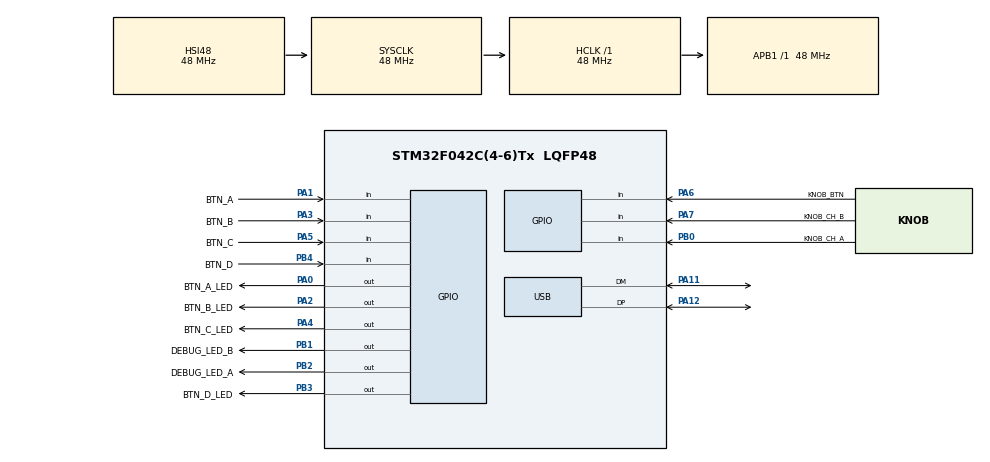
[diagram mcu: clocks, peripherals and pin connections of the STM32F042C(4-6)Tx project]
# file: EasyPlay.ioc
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Mcu.Family=STM32F0
Mcu.Name=STM32F042C(4-6)Tx
Mcu.Package=LQFP48
NVIC.TIM2_IRQn=true\:0\:0\:false\:false\:true\:true\:true\:true
NVIC.USB_IRQn=true\:0\:0\:false\:false\:true\:true\:true\:true
PA0.GPIO_Label=BTN_A_LED
PA0.Signal=GPIO_Output
PA1.GPIO_Label=BTN_A
PA1.Signal=GPIO_Input
PA11.Mode=Device
PA11.Signal=USB_DM
PA12.Mode=Device
PA12.Signal=USB_DP
PA13.Mode=Serial_Wire
PA13.Signal=SYS_SWDIO
PA14.Mode=Serial_Wire
PA14.Signal=SYS_SWCLK
PA2.GPIO_Label=BTN_B_LED
PA2.Signal=GPIO_Output
PA3.GPIO_Label=BTN_B
PA3.Signal=GPIO_Input
PA4.GPIO_Label=BTN_C_LED
PA4.Signal=GPIO_Output
PA5.GPIO_Label=BTN_C
PA5.Signal=GPIO_Input
PA6.GPIO_Label=KNOB_BTN
PA6.Signal=GPIO_Input
PA7.GPIO_Label=KNOB_CH_B
PA7.Signal=GPIO_Input
PB0.GPIO_Label=KNOB_CH_A
PB0.Signal=GPIO_Input
PB1.GPIO_Label=DEBUG_LED_B
PB1.Signal=GPIO_Output
PB2.GPIO_Label=DEBUG_LED_A
PB2.Signal=GPIO_Output
PB3.GPIO_Label=BTN_D_LED
PB3.Signal=GPIO_Output
PB4.GPIO_Label=BTN_D
PB4.Signal=GPIO_Input
ProjectManager.HeapSize=0x0
ProjectManager.StackSize=0x0
ProjectManager.TargetToolchain=STM32CubeIDE
RCC.AHBFreq_Value=48000000
RCC.APB1Freq_Value=48000000
RCC.APB1TimFreq_Value=48000000
RCC.HCLKFreq_Value=48000000
RCC.HSE_VALUE=25000000
RCC.SYSCLKFreq_VALUE=48000000
RCC.SYSCLKSource=RCC_SYSCLKSOURCE_HSI48
TIM2.AutoReloadPreload=TIM_AUTORELOAD_PRELOAD_ENABLE
TIM2.Period=48
TIM2.Prescaler=1000
USB_DEVICE.APP_RX_DATA_SIZE=15
USB_DEVICE.APP_TX_DATA_SIZE=15
USB_DEVICE.CLASS_NAME_FS=CDC
USB_DEVICE.PRODUCT_STRING_CDC_FS=EasyPlayDevice
USB_DEVICE.VirtualMode=Cdc
USB_DEVICE.VirtualModeFS=Cdc_FS
VP_TIM2_VS_ClockSourceINT.Mode=Internal
VP_USB_DEVICE_VS_USB_DEVICE_CDC_FS.Mode=CDC_FS
board=custom

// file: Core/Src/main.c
/* USER CODE BEGIN Header */
/**
 ******************************************************************************
 * @file           : main.c
 * @brief          : Main program body
 ******************************************************************************
 * @attention
 *
 * Copyright (c) 2022 STMicroelectronics.
 * All rights reserved.
 *
 * This software is licensed under terms that can be found in the LICENSE file
 * in the root directory of this software component.
 * If no LICENSE file comes with this software, it is provided AS-IS.
 *
 ******************************************************************************
 */
/* USER CODE END Header */
#include "main.h"
#include "usb_device.h"

/* USER CODE BEGIN Includes */
#include <debug_leds.h>
#include <tasks.h>
#include <ui_master.h>
#include <usb_comm.h>
/* USER CODE END Includes */

/* USER CODE BEGIN PD */
#define STABILIZING_PERIOD_MS 100
/* USER CODE END PD */

TIM_HandleTypeDef htim2;

void SystemClock_Config(void);
static void MX_GPIO_Init(void);
static void MX_TIM2_Init(void);

int main(void)
{

  /* MCU Configuration--------------------------------------------------------*/

  /* Reset of all peripherals, Initializes the Flash interface and the Systick. */
  HAL_Init();

  /* Configure the system clock */
  SystemClock_Config();

  /* Initialize all configured peripherals */
  MX_GPIO_Init();
  MX_USB_DEVICE_Init();
  MX_TIM2_Init();
  /* USER CODE BEGIN 2 */
  init_USB_queues();
  init_sws_debounce_data();
  HAL_Delay(STABILIZING_PERIOD_MS);
  /* USER CODE END 2 */

  /* Infinite loop */
  while (1) {

    /* USER CODE BEGIN 3 */
    run_schedule();
  }
  /* USER CODE END 3 */
}

void SystemClock_Config(void)
{
  RCC_OscInitTypeDef RCC_OscInitStruct = {0};
  RCC_ClkInitTypeDef RCC_ClkInitStruct = {0};
  RCC_PeriphCLKInitTypeDef PeriphClkInit = {0};

  /** Initializes the RCC Oscillators according to the specified parameters
  * in the RCC_OscInitTypeDef structure.
  */
  RCC_OscInitStruct.OscillatorType = RCC_OSCILLATORTYPE_HSI48;
  RCC_OscInitStruct.HSI48State = RCC_HSI48_ON;
  RCC_OscInitStruct.PLL.PLLState = RCC_PLL_NONE;
  if (HAL_RCC_OscConfig(&RCC_OscInitStruct) != HAL_OK)
  {
    Error_Handler();
  }

  /** Initializes the CPU, AHB and APB buses clocks
  */
  RCC_ClkInitStruct.ClockType = RCC_CLOCKTYPE_HCLK|RCC_CLOCKTYPE_SYSCLK
                              |RCC_CLOCKTYPE_PCLK1;
  RCC_ClkInitStruct.SYSCLKSource = RCC_SYSCLKSOURCE_HSI48;
  RCC_ClkInitStruct.AHBCLKDivider = RCC_SYSCLK_DIV1;
  RCC_ClkInitStruct.APB1CLKDivider = RCC_HCLK_DIV1;

  if (HAL_RCC_ClockConfig(&RCC_ClkInitStruct, FLASH_LATENCY_1) != HAL_OK)
  {
    Error_Handler();
  }
  PeriphClkInit.PeriphClockSelection = RCC_PERIPHCLK_USB;
  PeriphClkInit.UsbClockSelection = RCC_USBCLKSOURCE_HSI48;

  if (HAL_RCCEx_PeriphCLKConfig(&PeriphClkInit) != HAL_OK)
  {
    Error_Handler();
  }
}

static void MX_TIM2_Init(void)
{

  TIM_ClockConfigTypeDef sClockSourceConfig = {0};
  TIM_MasterConfigTypeDef sMasterConfig = {0};

  htim2.Instance = TIM2;
  htim2.Init.Prescaler = 1000;
  htim2.Init.CounterMode = TIM_COUNTERMODE_UP;
  htim2.Init.Period = 48;
  htim2.Init.ClockDivision = TIM_CLOCKDIVISION_DIV1;
  htim2.Init.AutoReloadPreload = TIM_AUTORELOAD_PRELOAD_ENABLE;
  if (HAL_TIM_Base_Init(&htim2) != HAL_OK)
  {
    Error_Handler();
  }
  sClockSourceConfig.ClockSource = TIM_CLOCKSOURCE_INTERNAL;
  if (HAL_TIM_ConfigClockSource(&htim2, &sClockSourceConfig) != HAL_OK)
  {
    Error_Handler();
  }
  sMasterConfig.MasterOutputTrigger = TIM_TRGO_RESET;
  sMasterConfig.MasterSlaveMode = TIM_MASTERSLAVEMODE_DISABLE;
  if (HAL_TIMEx_MasterConfigSynchronization(&htim2, &sMasterConfig) != HAL_OK)
  {
    Error_Handler();
  }
  /* USER CODE BEGIN TIM2_Init 2 */
  HAL_TIM_Base_Start_IT(&htim2);
  /* USER CODE END TIM2_Init 2 */

}

static void MX_GPIO_Init(void)
{
  GPIO_InitTypeDef GPIO_InitStruct = {0};

  /* GPIO Ports Clock Enable */
  __HAL_RCC_GPIOA_CLK_ENABLE();
  __HAL_RCC_GPIOB_CLK_ENABLE();

  /*Configure GPIO pin Output Level */
  HAL_GPIO_WritePin(GPIOA, BTN_A_LED_Pin|BTN_B_LED_Pin|BTN_C_LED_Pin, GPIO_PIN_RESET);

  /*Configure GPIO pin Output Level */
  HAL_GPIO_WritePin(GPIOB, DEBUG_LED_B_Pin|DEBUG_LED_A_Pin|BTN_D_LED_Pin, GPIO_PIN_RESET);

  /*Configure GPIO pins : BTN_A_LED_Pin BTN_B_LED_Pin BTN_C_LED_Pin */
  GPIO_InitStruct.Pin = BTN_A_LED_Pin|BTN_B_LED_Pin|BTN_C_LED_Pin;
  GPIO_InitStruct.Mode = GPIO_MODE_OUTPUT_PP;
  GPIO_InitStruct.Pull = GPIO_NOPULL;
  GPIO_InitStruct.Speed = GPIO_SPEED_FREQ_LOW;
  HAL_GPIO_Init(GPIOA, &GPIO_InitStruct);

  /*Configure GPIO pins : BTN_A_Pin BTN_B_Pin BTN_C_Pin KNOB_BTN_Pin
                           KNOB_CH_B_Pin */
  GPIO_InitStruct.Pin = BTN_A_Pin|BTN_B_Pin|BTN_C_Pin|KNOB_BTN_Pin
                          |KNOB_CH_B_Pin;
  GPIO_InitStruct.Mode = GPIO_MODE_INPUT;
  GPIO_InitStruct.Pull = GPIO_NOPULL;
  HAL_GPIO_Init(GPIOA, &GPIO_InitStruct);

  /*Configure GPIO pins : KNOB_CH_A_Pin BTN_D_Pin */
  GPIO_InitStruct.Pin = KNOB_CH_A_Pin|BTN_D_Pin;
  GPIO_InitStruct.Mode = GPIO_MODE_INPUT;
  GPIO_InitStruct.Pull = GPIO_NOPULL;
  HAL_GPIO_Init(GPIOB, &GPIO_InitStruct);

  /*Configure GPIO pins : DEBUG_LED_B_Pin DEBUG_LED_A_Pin BTN_D_LED_Pin */
  GPIO_InitStruct.Pin = DEBUG_LED_B_Pin|DEBUG_LED_A_Pin|BTN_D_LED_Pin;
  GPIO_InitStruct.Mode = GPIO_MODE_OUTPUT_PP;
  GPIO_InitStruct.Pull = GPIO_NOPULL;
  GPIO_InitStruct.Speed = GPIO_SPEED_FREQ_LOW;
  HAL_GPIO_Init(GPIOB, &GPIO_InitStruct);

}

void Error_Handler(void)
{
  /* USER CODE BEGIN Error_Handler_Debug */
  /* User can add his own implementation to report the HAL error return state */
  __disable_irq();
  while (1) {
    set_problem_LED_state(1);
  }
  /* USER CODE END Error_Handler_Debug */
}

#ifdef  USE_FULL_ASSERT
/**
  * @brief  Reports the name of the source file and the source line number
  *         where the assert_param error has occurred.
  * @param  file: pointer to the source file name
  * @param  line: assert_param error line source number
  * @retval None
  */
void assert_failed(uint8_t *file, uint32_t line)
{
  /* USER CODE BEGIN 6 */
  /* User can add his own implementation to report the file name and line
     number, ex: printf("Wrong parameters value: file %s on line %d\r\n", file,
     line) */
  /* USER CODE END 6 */
}
#endif /* USE_FULL_ASSERT */
